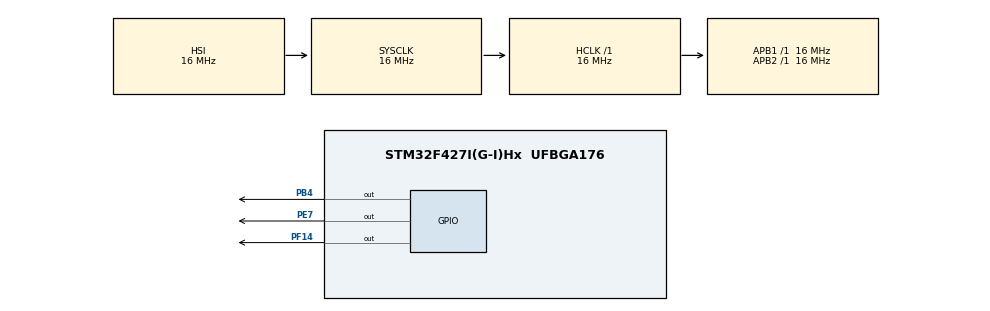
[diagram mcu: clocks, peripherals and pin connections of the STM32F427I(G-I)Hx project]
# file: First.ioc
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Mcu.Family=STM32F4
Mcu.Name=STM32F427I(G-I)Hx
Mcu.Package=UFBGA176
NVIC.PriorityGroup=NVIC_PRIORITYGROUP_4
NVIC.TIM1_UP_TIM10_IRQn=true\:0\:0\:false\:false\:true\:false
NVIC.TimeBase=TIM1_UP_TIM10_IRQn
NVIC.TimeBaseIP=TIM1
PB4.PinState=GPIO_PIN_SET
PB4.Signal=GPIO_Output
PE7.Signal=GPIO_Output
PF14.Signal=GPIO_Output
ProjectManager.HeapSize=0x200
ProjectManager.StackSize=0x400
ProjectManager.TargetToolchain=MDK-ARM V5
RCC.AHBFreq_Value=16000000
RCC.APB1Freq_Value=16000000
RCC.APB2Freq_Value=16000000
RCC.CortexFreq_Value=16000000
RCC.HSE_VALUE=25000000
RCC.HSI_VALUE=16000000
RCC.LSE_VALUE=32768
RCC.SYSCLKFreq_VALUE=16000000
RCC.VCOOutputFreq_Value=192000000
VP_SYS_VS_tim1.Mode=TIM1
board=First

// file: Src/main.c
/**
  ******************************************************************************
  * @file           : main.c
  * @brief          : Main program body
  ******************************************************************************
  * This notice applies to any and all portions of this file
  * that are not between comment pairs USER CODE BEGIN and
  * USER CODE END. Other portions of this file, whether
  * inserted by the user or by software development tools
  * are owned by their respective copyright owners.
  *
  * Copyright (c) 2018 STMicroelectronics International N.V.
  * All rights reserved.
  *
  * Redistribution and use in source and binary forms, with or without
  * modification, are permitted, provided that the following conditions are met:
  *
  * 1. Redistribution of source code must retain the above copyright notice,
  *    this list of conditions and the following disclaimer.
  * 2. Redistributions in binary form must reproduce the above copyright notice,
  *    this list of conditions and the following disclaimer in the documentation
  *    and/or other materials provided with the distribution.
  * 3. Neither the name of STMicroelectronics nor the names of other
  *    contributors to this software may be used to endorse or promote products
  *    derived from this software without specific written permission.
  * 4. This software, including modifications and/or derivative works of this
  *    software, must execute solely and exclusively on microcontroller or
  *    microprocessor devices manufactured by or for STMicroelectronics.
  * 5. Redistribution and use of this software other than as permitted under
  *    this license is void and will automatically terminate your rights under
  *    this license.
  *
  * THIS SOFTWARE IS PROVIDED BY STMICROELECTRONICS AND CONTRIBUTORS "AS IS"
  * AND ANY EXPRESS, IMPLIED OR STATUTORY WARRANTIES, INCLUDING, BUT NOT
  * LIMITED TO, THE IMPLIED WARRANTIES OF MERCHANTABILITY, FITNESS FOR A
  * PARTICULAR PURPOSE AND NON-INFRINGEMENT OF THIRD PARTY INTELLECTUAL PROPERTY
  * RIGHTS ARE DISCLAIMED TO THE FULLEST EXTENT PERMITTED BY LAW. IN NO EVENT
  * SHALL STMICROELECTRONICS OR CONTRIBUTORS BE LIABLE FOR ANY DIRECT, INDIRECT,
  * INCIDENTAL, SPECIAL, EXEMPLARY, OR CONSEQUENTIAL DAMAGES (INCLUDING, BUT NOT
  * LIMITED TO, PROCUREMENT OF SUBSTITUTE GOODS OR SERVICES; LOSS OF USE, DATA,
  * OR PROFITS; OR BUSINESS INTERRUPTION) HOWEVER CAUSED AND ON ANY THEORY OF
  * LIABILITY, WHETHER IN CONTRACT, STRICT LIABILITY, OR TORT (INCLUDING
  * NEGLIGENCE OR OTHERWISE) ARISING IN ANY WAY OUT OF THE USE OF THIS SOFTWARE,
  * EVEN IF ADVISED OF THE POSSIBILITY OF SUCH DAMAGE.
  *
  ******************************************************************************
  */
#include "main.h"
#include "stm32f4xx_hal.h"
#include "cmsis_os.h"

osThreadId defaultTaskHandle;

/* USER CODE BEGIN PV */
/* Private variables ---------------------------------------------------------*/

/* USER CODE END PV */

void SystemClock_Config(void);
static void MX_GPIO_Init(void);
void StartDefaultTask(void const * argument);

/* USER CODE BEGIN PFP */
/* Private function prototypes -----------------------------------------------*/

/* USER CODE END PFP */

int main(void)
{

  /* MCU Configuration----------------------------------------------------------*/

  /* Reset of all peripherals, Initializes the Flash interface and the Systick. */
  HAL_Init();

  /* Configure the system clock */
  SystemClock_Config();

  /* Initialize all configured peripherals */
  MX_GPIO_Init();
  /* USER CODE BEGIN 2 */
	//HAL_GPIO_WritePin(GPIOE,GPIO_PIN_7, GPIO_PIN_SET);
  /* USER CODE END 2 */

  /* Create the thread(s) */
  /* definition and creation of defaultTask */
  osThreadDef(defaultTask, StartDefaultTask, osPriorityNormal, 0, 128);
  defaultTaskHandle = osThreadCreate(osThread(defaultTask), NULL);

  /* Start scheduler */
  osKernelStart();

  /* We should never get here as control is now taken by the scheduler */

  /* Infinite loop */
  while (1)
  {

  /* USER CODE BEGIN 3 */
	HAL_GPIO_TogglePin(GPIOE,GPIO_PIN_7);
	HAL_Delay(1000);
	//HAL_GPIO_TogglePin(GPIOB,GPIO_PIN_4);
	//HAL_Delay(1000);
  }
  /* USER CODE END 3 */

}

void SystemClock_Config(void)
{

  RCC_OscInitTypeDef RCC_OscInitStruct;
  RCC_ClkInitTypeDef RCC_ClkInitStruct;

    /**Configure the main internal regulator output voltage
    */
  __HAL_RCC_PWR_CLK_ENABLE();

  __HAL_PWR_VOLTAGESCALING_CONFIG(PWR_REGULATOR_VOLTAGE_SCALE3);

    /**Initializes the CPU, AHB and APB busses clocks
    */
  RCC_OscInitStruct.OscillatorType = RCC_OSCILLATORTYPE_HSI;
  RCC_OscInitStruct.HSIState = RCC_HSI_ON;
  RCC_OscInitStruct.HSICalibrationValue = 16;
  RCC_OscInitStruct.PLL.PLLState = RCC_PLL_NONE;
  if (HAL_RCC_OscConfig(&RCC_OscInitStruct) != HAL_OK)
  {
    _Error_Handler(__FILE__, __LINE__);
  }

    /**Initializes the CPU, AHB and APB busses clocks
    */
  RCC_ClkInitStruct.ClockType = RCC_CLOCKTYPE_HCLK|RCC_CLOCKTYPE_SYSCLK
                              |RCC_CLOCKTYPE_PCLK1|RCC_CLOCKTYPE_PCLK2;
  RCC_ClkInitStruct.SYSCLKSource = RCC_SYSCLKSOURCE_HSI;
  RCC_ClkInitStruct.AHBCLKDivider = RCC_SYSCLK_DIV1;
  RCC_ClkInitStruct.APB1CLKDivider = RCC_HCLK_DIV1;
  RCC_ClkInitStruct.APB2CLKDivider = RCC_HCLK_DIV1;

  if (HAL_RCC_ClockConfig(&RCC_ClkInitStruct, FLASH_LATENCY_0) != HAL_OK)
  {
    _Error_Handler(__FILE__, __LINE__);
  }

    /**Configure the Systick interrupt time
    */
  HAL_SYSTICK_Config(HAL_RCC_GetHCLKFreq()/1000);

    /**Configure the Systick
    */
  HAL_SYSTICK_CLKSourceConfig(SYSTICK_CLKSOURCE_HCLK);

  /* SysTick_IRQn interrupt configuration */
  HAL_NVIC_SetPriority(SysTick_IRQn, 15, 0);
}

/** Configure pins as
        * Analog
        * Input
        * Output
        * EVENT_OUT
        * EXTI
*/
static void MX_GPIO_Init(void)
{

  GPIO_InitTypeDef GPIO_InitStruct;

  /* GPIO Ports Clock Enable */
  __HAL_RCC_GPIOB_CLK_ENABLE();
  __HAL_RCC_GPIOF_CLK_ENABLE();
  __HAL_RCC_GPIOE_CLK_ENABLE();

  /*Configure GPIO pin Output Level */
  HAL_GPIO_WritePin(GPIOB, GPIO_PIN_4, GPIO_PIN_SET);

  /*Configure GPIO pin Output Level */
  HAL_GPIO_WritePin(GPIOF, GPIO_PIN_14, GPIO_PIN_RESET);

  /*Configure GPIO pin Output Level */
  HAL_GPIO_WritePin(GPIOE, GPIO_PIN_7, GPIO_PIN_RESET);

  /*Configure GPIO pin : PB4 */
  GPIO_InitStruct.Pin = GPIO_PIN_4;
  GPIO_InitStruct.Mode = GPIO_MODE_OUTPUT_PP;
  GPIO_InitStruct.Pull = GPIO_NOPULL;
  GPIO_InitStruct.Speed = GPIO_SPEED_FREQ_LOW;
  HAL_GPIO_Init(GPIOB, &GPIO_InitStruct);

  /*Configure GPIO pin : PF14 */
  GPIO_InitStruct.Pin = GPIO_PIN_14;
  GPIO_InitStruct.Mode = GPIO_MODE_OUTPUT_PP;
  GPIO_InitStruct.Pull = GPIO_NOPULL;
  GPIO_InitStruct.Speed = GPIO_SPEED_FREQ_LOW;
  HAL_GPIO_Init(GPIOF, &GPIO_InitStruct);

  /*Configure GPIO pin : PE7 */
  GPIO_InitStruct.Pin = GPIO_PIN_7;
  GPIO_InitStruct.Mode = GPIO_MODE_OUTPUT_PP;
  GPIO_InitStruct.Pull = GPIO_NOPULL;
  GPIO_InitStruct.Speed = GPIO_SPEED_FREQ_LOW;
  HAL_GPIO_Init(GPIOE, &GPIO_InitStruct);

}

/* StartDefaultTask function */
void StartDefaultTask(void const * argument)
{

  for(;;)
  {
    osDelay(1);
  }
}

void HAL_TIM_PeriodElapsedCallback(TIM_HandleTypeDef *htim)
{
  if (htim->Instance == TIM1) {
    HAL_IncTick();
  }
}

void _Error_Handler(char *file, int line)
{
  while(1)
  {
  }
}

/************************ (C) COPYRIGHT STMicroelectronics *****END OF FILE****/
